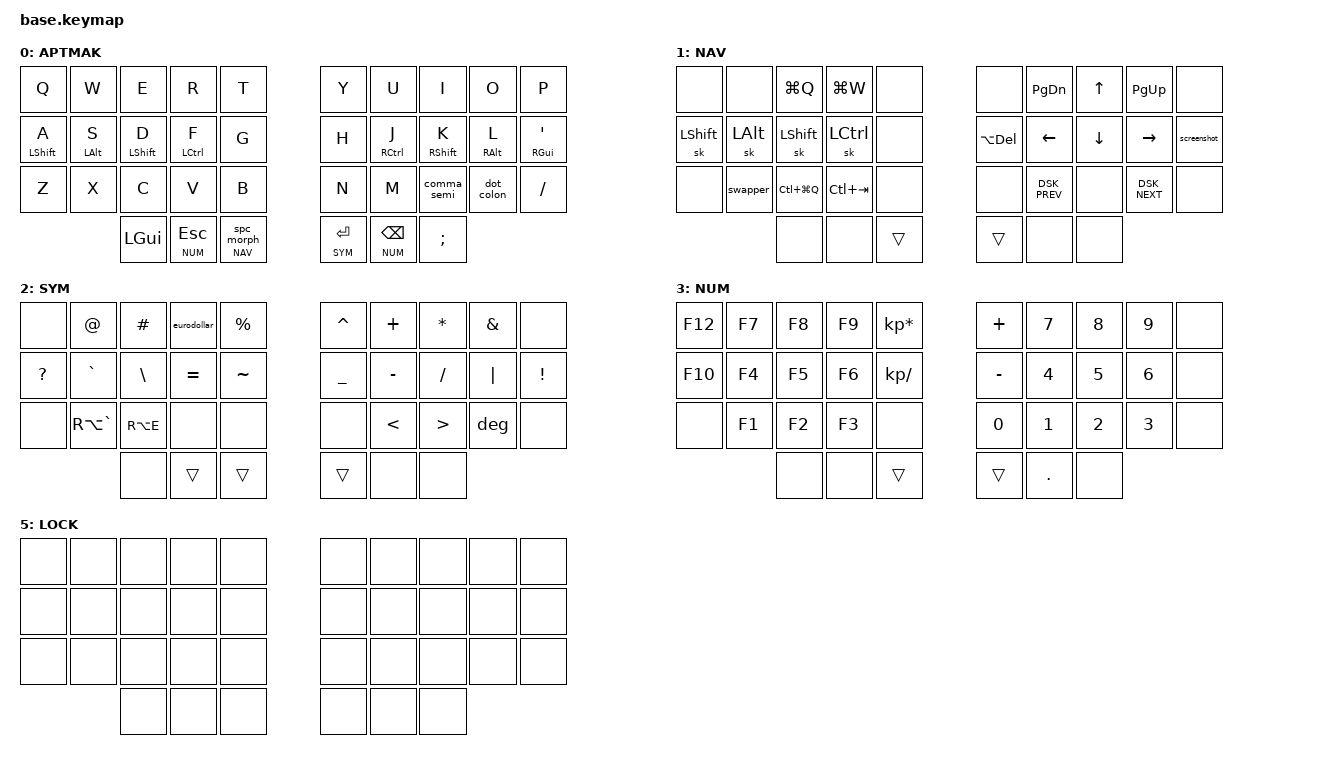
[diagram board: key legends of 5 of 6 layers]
#include <behaviors.dtsi>
#include <dt-bindings/zmk/keys.h>
#include <dt-bindings/zmk/outputs.h>


// layers ID definition
#define BASE 0
#define NAV 1
#define SYM 2
#define NUM 3
#define ADJ 4
#define LOCKL 5

#define ___ &none

#include "combos.dtsi"
#include "extra_keys.h"
#if WIRELESS
    #include <dt-bindings/zmk/bt.h>
    #define BTL1  &bt BT_CLR   &bt BT_SEL 2  &pc_connect   &osx_connect
    #define BTL2  ___          &bt BT_SEL 4  &bt BT_SEL 3  &out OUT_TOG
#else
    #define BTL1  ___   ___   ___   ___
    #define BTL2  ___   ___   ___   ___
#endif

// tapping term definition
#define TAP_TERM_MS 200
#define QUICK_TAP_MS 125

// macros definition
#define meh LG(LC(LALT))
#define hyper LG(LC(LS(LALT)))
#define deg RA(LS(N8))

// OSX specific macros
#define undo LG(Z)
#define redo LG(LS(Z))
#define DSK_PREV LC(LEFT)
#define DSK_NEXT LC(RIGHT)
#define prev_win LG(TAB)
#define next_win LG(LS(TAB))

// 36 keys physical layout
#define LEFT_KEYS 0 1 2 3 4 10 11 12 13 14 20 21 22 23 24 // left-hand keys
#define RIGHT_KEYS 5 6 7 8 9 15 16 17 18 19 25 26 27 28 29 // right-hand keys
#define THUMBS 30 31 32 33 34 35 // thumb keys

// tune mod tap
&mt {
    flavor = "tap-preferred";
    tapping_term_ms = <200>;
};

// layer tap config
&lt {
    flavor = "balanced";
    tapping-term-ms = <TAP_TERM_MS>;
    quick-tap-ms = <QUICK_TAP_MS>;      // double-tap + hold repeats tap-key
};

// tune sticky key
&sk {
    release-after-ms = <1000>;
    quick-release;
};

// sticky layer config
&sl {
    release-after-ms = <700>;
};

// caps word settings
&caps_word {
    continue-list = <UNDERSCORE MINUS BSPC N1 N2 N3 N4 N5 N6 N7 N8 N9 N0>;
};


// main tree
/ {
    behaviors {
        // HOME ROW MODS
        hml: left_hand_positional_hold_tap {
            compatible = "zmk,behavior-hold-tap";
            label = "LEFT_POSITIONAL_HOLD_TAP";
            #binding-cells = <2>;
            flavor = "balanced";
            tapping-term-ms = <TAP_TERM_MS>;
            quick-tap-ms = <QUICK_TAP_MS>;       // double-tap + hold repeats tap-key
            require-prior-idle-ms = <150>;         // without PR #1387 use global-quick-tap instead
            bindings = <&kp>, <&kp>;
            hold-trigger-key-positions = <RIGHT_KEYS THUMBS>;
            hold-trigger-on-release;
        };

        hmr: right_hand_positional_hold_tap {
            compatible = "zmk,behavior-hold-tap";
            label = "RIGHT_POSITIONAL_HOLD_TAP";
            #binding-cells = <2>;
            flavor = "balanced";
            tapping-term-ms = <TAP_TERM_MS>;
            quick-tap-ms = <QUICK_TAP_MS>;       // double-tap + hold repeats tap-key
            require-prior-idle-ms = <150>;         // without PR #1387 use global-quick-tap instead
            bindings = <&kp>, <&kp>;
            hold-trigger-key-positions = <LEFT_KEYS THUMBS>;
            hold-trigger-on-release;
        };

        // TAP DANCES
        eurodollar: tap_dance_euro_dollar {
            compatible = "zmk,behavior-tap-dance";
            label = "TAP_DANCE_EURO_DOLLAR";
            #binding-cells = <0>;
            tapping-term-ms = <TAP_TERM_MS>;
            bindings = <&kp DLLR>, <&kp LA(N5)>;
        };
        prev_next_song: prev_next_song {
            compatible = "zmk,behavior-tap-dance";
            label = "PREV_NEXT_SONG";
            #binding-cells = <0>;
            tapping-term-ms = <TAP_TERM_MS>;
            bindings = <&kp C_NEXT>, <&kp C_PREV>;
        };
        screenshot: screenshot { // single-tap: area selector, double-tap: full-screen
            compatible = "zmk,behavior-tap-dance";
            label = "SCREENSHOT";
            #binding-cells = <0>;
            tapping-term-ms = <TAP_TERM_MS>;
            bindings = <&kp LG(LS(NUMBER_4))>, <&kp LG(LS(NUMBER_3))>;
        };

        // tap: sticky-shift | lshft + tap: caps-word | hold: set in keymap (HYPER)
        ss_cw: ss_cw {
            compatible = "zmk,behavior-mod-morph";
            label = "SS_CW";
            #binding-cells = <0>;
            bindings = <&sk LSHFT>, <&caps_word>;
            mods = <(MOD_LSFT|MOD_RSFT)>;
        };
        lt_shft: lt_shft {
            compatible = "zmk,behavior-hold-tap";
            label = "LT_SHFT";
            #binding-cells = <2>;
            tapping-term-ms = <TAP_TERM_MS>;
            quick-tap-ms = <QUICK_TAP_MS>;
            flavor = "balanced";
            bindings = <&kp>, <&ss_cw>;
        };

        // tap: space | shft + tap: dot -> space -> sticky shift | hold: activate layer
        spc_morph: spc_morph {
            compatible = "zmk,behavior-mod-morph";
            label = "SPC_MORPH";
            #binding-cells = <0>;
            bindings = <&kp SPACE>, <&dot_spc>;
            mods = <(MOD_LSFT)>;
        };
        lt_spc: lt_spc {
            compatible = "zmk,behavior-hold-tap";
            label = "LT_SPC";
            #binding-cells = <2>;
            tapping-term-ms = <TAP_TERM_MS>;
            quick-tap-ms = <QUICK_TAP_MS>;
            flavor = "balanced";
            bindings = <&mo>, <&spc_morph>;
        };

        // Alt+Tab swapper, requires PR #1366
        swapper: swapper{
            compatible = "zmk,behavior-tri-state";
            label = "SWAPPER";
            #binding-cells = <0>;
            bindings = <&kt LGUI>, <&kp TAB>, <&kt LGUI>;
            ignored-key-positions = <31>; // the key being held for the layer activation
        };

        //usefull mod-morphs
        dot_colon: dot_colon {
            compatible = "zmk,behavior-mod-morph";
            label = "DOT_TO_COLON";
            #binding-cells = <0>;
            bindings = <&kp DOT>, <&kp COLON>;
            mods = <(MOD_LSFT|MOD_RSFT)>;
        };
        comma_semi: comma_semi {
            compatible = "zmk,behavior-mod-morph";
            label = "COMMA_TO_SEMICOLON";
            #binding-cells = <0>;
            bindings = <&kp COMMA>, <&kp SEMICOLON>;
            mods = <(MOD_LSFT|MOD_RSFT)>;
        };
        quest_excl: quest_excl {
            compatible = "zmk,behavior-mod-morph";
            label = "quest_to_excl";
            #binding-cells = <0>;
            bindings = <&kp QUESTION>, <&kp EXCLAMATION>;
            mods = <(MOD_LSFT|MOD_RSFT)>;
        };
        single_to_doublequote: single_to_doublequote {
            compatible = "zmk,behavior-mod-morph";
            label = "SINGLE_TO_DOUBLEQUOTE";
            #binding-cells = <0>;
            bindings = <&kp SINGLE_QUOTE>, <&kp DOUBLE_QUOTES>;
            mods = <(MOD_LSFT|MOD_RSFT)>;
        };
    };

    // macros
    macros {
        sel_word: select_word {
            label = "ZM_SELECT_WORD";
            compatible = "zmk,behavior-macro";
            #binding-cells = <0>;
            bindings
                = <&macro_press &kp LCTRL>
                , <&macro_tap &kp LEFT>
                , <&macro_press &kp LSHFT>
                , <&macro_tap &kp RIGHT>
                , <&macro_release &kp LSHFT &kp LCTRL>
                ;
        };

        dot_spc: dot_spc{
            label = "ZM_DOT_SPACE";
            compatible = "zmk,behavior-macro";
            #binding-cells = <0>;
            wait-ms = <0>;
            tap-ms = <5>;
            bindings = <&kp DOT &kp SPACE &sk LSHFT>;
        };

        // Windows sleep key (fix LOCK not working on Windows)
        win_sleep: win_sleep{
            label = "ZM_WIN_SLEEP";
            compatible = "zmk,behavior-macro";
            #binding-cells = <0>;
            wait-ms = <100>;
            tap-ms = <5>;
            bindings = <&kp LG(X) &kp U &kp S>;
        };

        pc_connect: pc_connect{
            label = "ZM_PC_CONNECT";
            compatible = "zmk,behavior-macro";
            #binding-cells = <0>;
            wait-ms = <100>;
            tap-ms = <5>;
            bindings = <&bt BT_SEL 1 &to BASE>;
        };

        osx_connect: osx_connect{
            label = "ZM_PC_CONNECT";
            compatible = "zmk,behavior-macro";
            #binding-cells = <0>;
            wait-ms = <100>;
            tap-ms = <5>;
            bindings = <&bt BT_SEL 0 &to BASE>;
        };

        macro_par: macro_par{
            label = "ZM_PAR";
            compatible = "zmk,behavior-macro";
            #binding-cells = <0>;
            wait-ms = <0>;
            tap-ms = <5>;
            bindings = <&kp LPAR &kp RPAR &kp LEFT>;
        };
        macro_bkt: macro_bkt{
            label = "ZM_BKT";
            compatible = "zmk,behavior-macro";
            #binding-cells = <0>;
            wait-ms = <0>;
            tap-ms = <5>;
            bindings = <&kp LBKT &kp RBKT &kp LEFT>;
        };
        macro_brc: macro_brc{
            label = "ZM_BRC";
            compatible = "zmk,behavior-macro";
            #binding-cells = <0>;
            wait-ms = <0>;
            tap-ms = <5>;
            bindings = <&kp LBRC &kp RBRC &kp LEFT>;
        };
        macro_deg_win: macro_deg_win{
            label = "ZM_DEG";
            compatible = "zmk,behavior-macro";
            #binding-cells = <0>;
            wait-ms = <0>;
            tap-ms = <5>;
            bindings
                = <&macro_press   &kp LALT>
                , <&macro_tap     &kp KP_N0 &kp KP_N1 &kp KP_N7 &kp KP_N6>
                , <&macro_release &kp LALT>
                ;
        };
    };

    conditional_layers {
        compatible = "zmk,conditional-layers";
        tri_layer {
            if-layers = <NAV SYM>;
            then-layer = <ADJ>;
        };
    };

    keymap {
        compatible = "zmk,keymap";

        default_layer {
            label = "APTMAK";
            bindings = <
             //╭──────────────┬──────────────┬──────────────┬──────────────┬──────────────╮     ╭──────────────┬──────────────┬──────────────┬──────────────┬──────────────╮
                &kp Q            &kp W          &kp E          &kp R         &kp T                 &kp Y          &kp U          &kp I          &kp O          &kp P
             //├──────────────┼──────────────┼──────────────┼──────────────┼──────────────┤     ├──────────────┼──────────────┼──────────────┼──────────────┼──────────────┤
                &hml LSHIFT A   &hml LALT S    &hml LSHIFT D  &hml LCTRL F   &kp G                 &kp H          &hmr RCTRL J    &hmr RSHIFT K  &hmr RALT L    &hmr RGUI SINGLE_QUOTE
             //├──────────────┼──────────────┼──────────────┼──────────────┼──────────────┤     ├──────────────┼──────────────┼──────────────┼──────────────┼──────────────┤
                &kp Z            &kp X          &kp C          &kp V         &kp B                   &kp N            &kp M     &comma_semi     &dot_colon     &kp SLASH
             //╰──────────────┴──────────────┼──────────────┼──────────────┼──────────────┤     ├──────────────┼──────────────┼──────────────┼──────────────┴──────────────╯
                                              &kp LGUI        &lt NUM ESC    &lt_spc NAV 0       &lt SYM RET    &lt NUM BSPC   &kp SEMICOLON
             //                              ╰──────────────┴──────────────┴──────────────╯     ╰──────────────┴──────────────┴──────────────╯
            >;
        };

        nav_layer{
            label = "NAV";
            bindings = <
             //╭──────────────┬──────────────┬──────────────┬──────────────┬──────────────╮     ╭──────────────┬──────────────┬──────────────┬──────────────┬──────────────╮
                ___            ___            &kp LG(Q)      &kp LG(W)      ___                  ___            &kp PG_DN      &kp UP         &kp PG_UP      ___
             //├──────────────┼──────────────┼──────────────┼──────────────┼──────────────┤     ├──────────────┼──────────────┼──────────────┼──────────────┼──────────────┤
                &sk LSHIFT      &sk LALT       &sk LSHFT      &sk LCTRL      ___                  &kp LA(DEL)    &kp LEFT       &kp DOWN       &kp RIGHT      &screenshot
             //├──────────────┼──────────────┼──────────────┼──────────────┼──────────────┤     ├──────────────┼──────────────┼──────────────┼──────────────┼──────────────┤
                ___            &swapper       &kp LC(LG(Q))  &kp LC(TAB)    ___                  ___            &kp DSK_PREV   ___            &kp DSK_NEXT   ___
             //╰──────────────┴──────────────┼──────────────┼──────────────┼──────────────┤     ├──────────────┼──────────────┼──────────────┼──────────────┴──────────────╯
                                              ___            ___            &trans               &trans         ___            ___
             //                              ╰──────────────┴──────────────┴──────────────╯     ╰──────────────┴──────────────┴──────────────╯
            >;
        };

        symbols {
            label = "SYM";
            bindings = <
             //╭──────────────┬──────────────┬──────────────┬──────────────┬──────────────╮     ╭──────────────┬──────────────┬──────────────┬──────────────┬──────────────╮
                ___            &kp AT         &kp HASH       &eurodollar    &kp PERCENT          &kp CARET      &kp PLUS       &kp ASTRK      &kp AMPS       ___
             //├──────────────┼──────────────┼──────────────┼──────────────┼──────────────┤     ├──────────────┼──────────────┼──────────────┼──────────────┼──────────────┤
                &kp QUESTION   &kp GRAVE      &kp BSLH       &kp EQUAL      &kp TILDE            &kp UNDER      &kp MINUS      &kp SLASH      &kp PIPE       &kp EXCL
             //├──────────────┼──────────────┼──────────────┼──────────────┼──────────────┤     ├──────────────┼──────────────┼──────────────┼──────────────┼──────────────┤
                ___            &kp RA(GRAVE)  &kp RA(E)      ___            ___                  ___            &kp LT         &kp GT         &kp deg        ___
             //╰──────────────┴──────────────┼──────────────┼──────────────┼──────────────┤     ├──────────────┼──────────────┼──────────────┼──────────────┴──────────────╯
                                              ___            &trans         &trans               &trans         ___            ___
             //                              ╰──────────────┴──────────────┴──────────────╯     ╰──────────────┴──────────────┴──────────────╯
            >;
        };

        num_layer{
            label = "NUM";
            bindings = <
             //╭──────────────┬──────────────┬──────────────┬──────────────┬──────────────╮     ╭──────────────┬──────────────┬──────────────┬──────────────┬──────────────╮
                &kp F12        &kp F7         &kp F8         &kp F9         &kp KP_MULTIPLY      &kp PLUS    &kp N7      &kp N8      &kp N9      ___
             //├──────────────┼──────────────┼──────────────┼──────────────┼──────────────┤     ├──────────────┼──────────────┼──────────────┼──────────────┼──────────────┤
                &kp F10        &kp F4         &kp F5         &kp F6         &kp KP_DIVIDE        &kp MINUS   &kp N4      &kp N5      &kp N6      ___
             //├──────────────┼──────────────┼──────────────┼──────────────┼──────────────┤     ├──────────────┼──────────────┼──────────────┼──────────────┼──────────────┤
                ___            &kp F1         &kp F2         &kp F3         ___                  &kp N0            &kp N1      &kp N2      &kp N3      ___
             //╰──────────────┴──────────────┼──────────────┼──────────────┼──────────────┤     ├──────────────┼──────────────┼──────────────┼──────────────┴──────────────╯
                                              ___            ___            &trans               &trans      &kp DOT        ___
             //                              ╰──────────────┴──────────────┴──────────────╯     ╰──────────────┴──────────────┴──────────────╯
            >;
        };

        adj_layer {
            label = "ADJ";
            bindings = <
             //╭──────────────┬──────────────┬──────────────┬──────────────┬──────────────╮     ╭──────────────┬──────────────┬──────────────┬──────────────┬──────────────╮
                ___            ___            &to 0          &to BASE       &bootloader          &bootloader    &kp C_PP       &kp C_NEXT     &kp C_PREV     ___
             //├──────────────┼──────────────┼──────────────┼──────────────┼──────────────┤     ├──────────────┼──────────────┼──────────────┼──────────────┼──────────────┤
                BTL1                                                        &sys_reset           &sys_reset     &kp C_VOL_DN   &kp C_VOL_UP   &kp C_MUTE     ___
             //├──────────────┼──────────────┼──────────────┼──────────────┼──────────────┤     ├──────────────┼──────────────┼──────────────┼──────────────┼──────────────┤
                BTL2                                                        ___                  ___            &kp C_BRI_DN   &kp C_BRI_UP   ___            ___
             //╰──────────────┴──────────────┼──────────────┼──────────────┼──────────────┤     ├──────────────┼──────────────┼──────────────┼──────────────┴──────────────╯
                                              ___            ___            ___                  ___            ___            ___
             //                              ╰──────────────┴──────────────┴──────────────╯     ╰──────────────┴──────────────┴──────────────╯
            >;
        };

        lock_layer {
            label = "LOCK";
            bindings = <
             //╭──────────────┬──────────────┬──────────────┬──────────────┬──────────────╮     ╭──────────────┬──────────────┬──────────────┬──────────────┬──────────────╮
                ___            ___            ___            ___            ___                  ___            ___            ___            ___            ___
             //├──────────────┼──────────────┼──────────────┼──────────────┼──────────────┤     ├──────────────┼──────────────┼──────────────┼──────────────┼──────────────┤
                ___            ___            ___            ___            ___                  ___            ___            ___            ___            ___
             //├──────────────┼──────────────┼──────────────┼──────────────┼──────────────┤     ├──────────────┼──────────────┼──────────────┼──────────────┼──────────────┤
                ___            ___            ___            ___            ___                  ___            ___            ___            ___            ___
             //╰──────────────┴──────────────┼──────────────┼──────────────┼──────────────┤     ├──────────────┼──────────────┼──────────────┼──────────────┴──────────────╯
                                              ___            ___            ___                  ___            ___            ___
             //                              ╰──────────────┴──────────────┴──────────────╯     ╰──────────────┴──────────────┴──────────────╯
            >;
        };

    };
};
